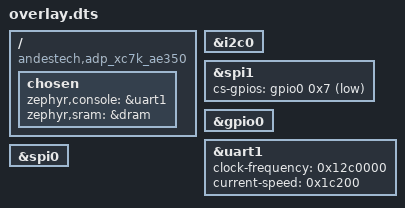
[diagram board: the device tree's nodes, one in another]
/ {
	compatible = "andestech,adp_xc7k_ae350";
	chosen {
		zephyr,console = &uart1;
		zephyr,sram = &dram;
	};
};
&i2c0{
	status = "okay";
};
&spi1{
	status = "okay";
	cs-gpios = < &gpio0 0x7 0x1 >;
};
&gpio0{
	status = "okay";
};
&uart1{
	status = "okay";
	clock-frequency = < 0x12c0000 >;
	current-speed = < 0x1c200 >;
};
&spi0{
	status = "okay";
};
